VERSION ""

NS_ :

BS_:

BU_:

BO_ 2 measurements_3: 2 Vector__XXX
 SG_ motor_rpm : 0|16@1+ (0.1,-3276.75) [-3276.75|3276.75] "RPM" Vector__XXX

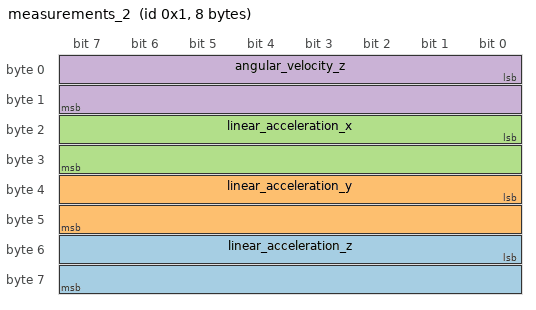
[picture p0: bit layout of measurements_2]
BO_ 1 measurements_2: 8 Vector__XXX
 SG_ linear_acceleration_z : 48|16@1+ (0.001,-32.7675) [-32.7675|32.7675] "m/s^2" Vector__XXX
 SG_ linear_acceleration_y : 32|16@1+ (0.001,-32.7675) [-32.7675|32.7675] "m/s^2" Vector__XXX
 SG_ linear_acceleration_x : 16|16@1+ (0.001,-32.7675) [-32.7675|32.7675] "m/s^2" Vector__XXX
 SG_ angular_velocity_z : 0|16@1+ (0.0002,-6.5535) [-6.5535|6.5535] "rad/s" Vector__XXX

BO_ 0 measurements_1: 8 Vector__XXX
 SG_ angular_velocity_y : 48|16@1+ (0.0002,-6.5535) [-6.5535|6.5535] "rad/s" Vector__XXX
 SG_ angular_velocity_x : 32|16@1+ (0.0002,-6.5535) [-6.5535|6.5535] "rad/s" Vector__XXX
 SG_ line_sensor_9 : 8|1@1+ (1,0) [0|1] "" Vector__XXX
 SG_ line_sensor_8 : 7|1@1+ (1,0) [0|1] "" Vector__XXX
 SG_ line_sensor_7 : 6|1@1+ (1,0) [0|1] "" Vector__XXX
 SG_ line_sensor_6 : 5|1@1+ (1,0) [0|1] "" Vector__XXX
 SG_ line_sensor_5 : 4|1@1+ (1,0) [0|1] "" Vector__XXX
 SG_ line_sensor_4 : 3|1@1+ (1,0) [0|1] "" Vector__XXX
 SG_ line_sensor_32 : 31|1@1+ (1,0) [0|1] "" Vector__XXX
 SG_ line_sensor_31 : 30|1@1+ (1,0) [0|1] "" Vector__XXX
 SG_ line_sensor_30 : 29|1@1+ (1,0) [0|1] "" Vector__XXX
 SG_ line_sensor_3 : 2|1@1+ (1,0) [0|1] "" Vector__XXX
 SG_ line_sensor_29 : 28|1@1+ (1,0) [0|1] "" Vector__XXX
 SG_ line_sensor_28 : 27|1@1+ (1,0) [0|1] "" Vector__XXX
 SG_ line_sensor_27 : 26|1@1+ (1,0) [0|1] "" Vector__XXX
 SG_ line_sensor_26 : 25|1@1+ (1,0) [0|1] "" Vector__XXX
 SG_ line_sensor_25 : 24|1@1+ (1,0) [0|1] "" Vector__XXX
 SG_ line_sensor_24 : 23|1@1+ (1,0) [0|1] "" Vector__XXX
 SG_ line_sensor_23 : 22|1@1+ (1,0) [0|1] "" Vector__XXX
 SG_ line_sensor_22 : 21|1@1+ (1,0) [0|1] "" Vector__XXX
 SG_ line_sensor_21 : 20|1@1+ (1,0) [0|1] "" Vector__XXX
 SG_ line_sensor_20 : 19|1@1+ (1,0) [0|1] "" Vector__XXX
 SG_ line_sensor_2 : 1|1@1+ (1,0) [0|1] "" Vector__XXX
 SG_ line_sensor_19 : 18|1@1+ (1,0) [0|1] "" Vector__XXX
 SG_ line_sensor_18 : 17|1@1+ (1,0) [0|1] "" Vector__XXX
 SG_ line_sensor_17 : 16|1@1+ (1,0) [0|1] "" Vector__XXX
 SG_ line_sensor_16 : 15|1@1+ (1,0) [0|1] "" Vector__XXX
 SG_ line_sensor_15 : 14|1@1+ (1,0) [0|1] "" Vector__XXX
 SG_ line_sensor_14 : 13|1@1+ (1,0) [0|1] "" Vector__XXX
 SG_ line_sensor_13 : 12|1@1+ (1,0) [0|1] "" Vector__XXX
 SG_ line_sensor_12 : 11|1@1+ (1,0) [0|1] "" Vector__XXX
 SG_ line_sensor_11 : 10|1@1+ (1,0) [0|1] "" Vector__XXX
 SG_ line_sensor_10 : 9|1@1+ (1,0) [0|1] "" Vector__XXX
 SG_ line_sensor_1 : 0|1@1+ (1,0) [0|1] "" Vector__XXX

BA_DEF_  "BusType" STRING ;
BA_DEF_DEF_  "BusType" "";
BA_ "BusType" "CAN";
